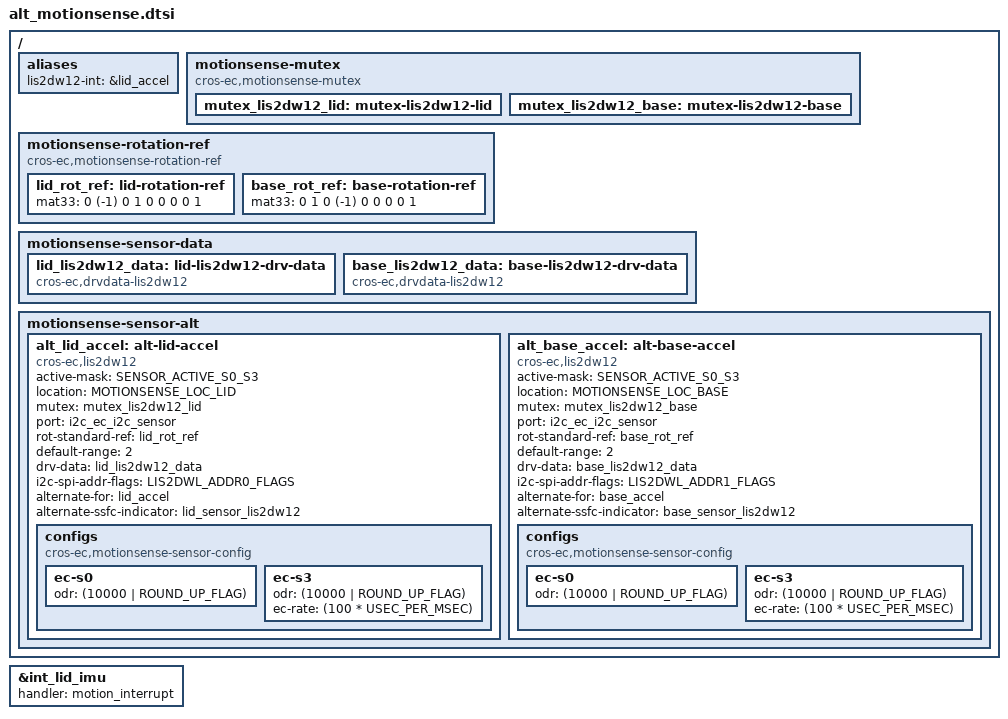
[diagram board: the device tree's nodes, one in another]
/* Copyright 2024 The ChromiumOS Authors
 * Use of this source code is governed by a BSD-style license that can be
 * found in the LICENSE file.
 */

#include <dt-bindings/motionsense/utils.h>

/ {
	aliases {
		/*
		 * Interrupt bindings for sensor devices.
		 */
		lis2dw12-int = &lid_accel;
	};

	/*
	 * Declare mutexes used by sensor drivers.
	 * A mutex node is used to create an instance of mutex_t.
	 * A mutex node is referenced by a sensor node if the
	 * corresponding sensor driver needs to use the
	 * instance of the mutex.
	 */
	motionsense-mutex {
		compatible = "cros-ec,motionsense-mutex";
		mutex_lis2dw12_lid: mutex-lis2dw12-lid {
		};
		mutex_lis2dw12_base: mutex-lis2dw12-base {
		};
	};

	/* Rotation matrix used by drivers. */
	motionsense-rotation-ref {
		compatible = "cros-ec,motionsense-rotation-ref";
		lid_rot_ref: lid-rotation-ref {
			mat33 = <0 (-1) 0
				 1 0 0
				 0 0 1>;
		};
		base_rot_ref: base-rotation-ref {
			mat33 = <0 1 0
				 (-1) 0 0
				 0 0 1>;
		};
	};

	/* Driver specific data. */
	motionsense-sensor-data {
		lid_lis2dw12_data: lid-lis2dw12-drv-data {
			compatible = "cros-ec,drvdata-lis2dw12";
			status = "okay";
		};
		base_lis2dw12_data: base-lis2dw12-drv-data {
			compatible = "cros-ec,drvdata-lis2dw12";
			status = "okay";
		};
	};

	/* List of motion sensors that creates motion_sensors array. */
	motionsense-sensor-alt {
		alt_lid_accel: alt-lid-accel {
			compatible = "cros-ec,lis2dw12";
			status = "okay";

			active-mask = "SENSOR_ACTIVE_S0_S3";
			location = "MOTIONSENSE_LOC_LID";
			mutex = <&mutex_lis2dw12_lid>;
			port = <&i2c_ec_i2c_sensor>;
			rot-standard-ref = <&lid_rot_ref>;
			default-range = <2>;
			drv-data = <&lid_lis2dw12_data>;
			i2c-spi-addr-flags = "LIS2DWL_ADDR0_FLAGS";
			alternate-for = <&lid_accel>;
			alternate-ssfc-indicator = <&lid_sensor_lis2dw12>;
			configs {
				compatible =
					"cros-ec,motionsense-sensor-config";
				ec-s0 {
					odr = <(10000 | ROUND_UP_FLAG)>;
				};
				ec-s3 {
					odr = <(10000 | ROUND_UP_FLAG)>;
					ec-rate = <(100 * USEC_PER_MSEC)>;
				};
			};
		};

		alt_base_accel: alt-base-accel {
			compatible = "cros-ec,lis2dw12";
			status = "okay";

			active-mask = "SENSOR_ACTIVE_S0_S3";
			location = "MOTIONSENSE_LOC_BASE";
			mutex = <&mutex_lis2dw12_base>;
			port = <&i2c_ec_i2c_sensor>;
			rot-standard-ref = <&base_rot_ref>;
			default-range = <2>;
			drv-data = <&base_lis2dw12_data>;
			i2c-spi-addr-flags = "LIS2DWL_ADDR1_FLAGS";
			alternate-for = <&base_accel>;
			alternate-ssfc-indicator = <&base_sensor_lis2dw12>;
			configs {
				compatible =
					"cros-ec,motionsense-sensor-config";
				ec-s0 {
					odr = <(10000 | ROUND_UP_FLAG)>;
				};
				ec-s3 {
					odr = <(10000 | ROUND_UP_FLAG)>;
					ec-rate = <(100 * USEC_PER_MSEC)>;
				};
			};
		};
	};
};

&int_lid_imu {
	handler = "motion_interrupt";
};
